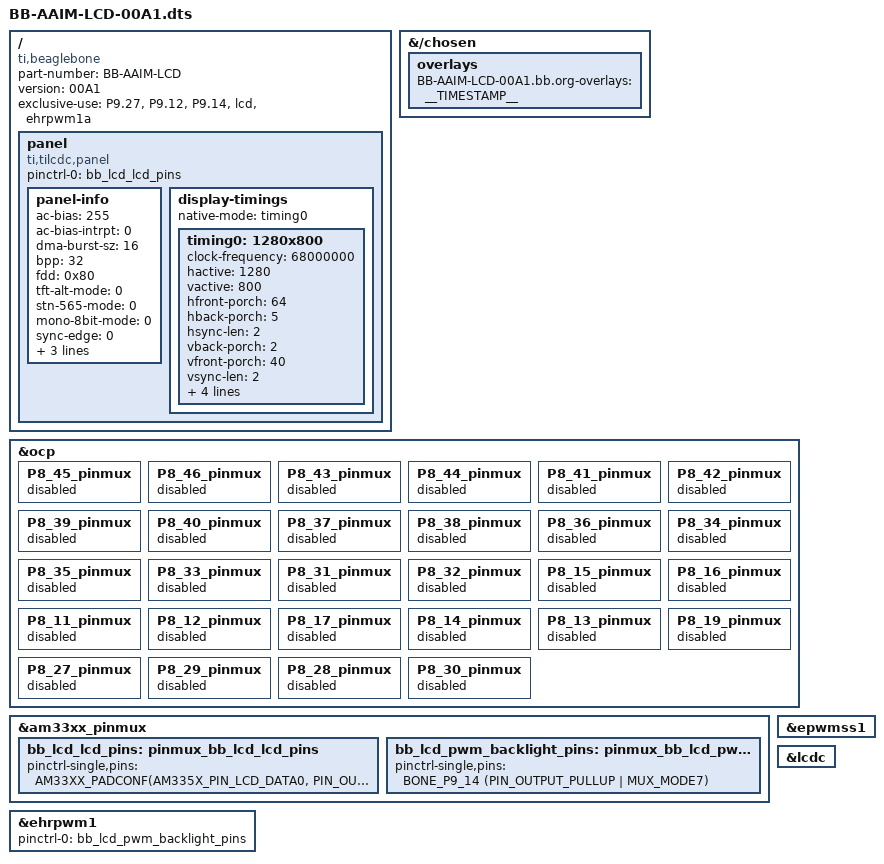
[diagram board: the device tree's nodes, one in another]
// SPDX-License-Identifier: GPL-2.0-only
/*
 * Copyright (C) 2012 Texas Instruments Incorporated - https://www.ti.com/
 */

/dts-v1/;
/plugin/;

#include <dt-bindings/board/am335x-bbw-bbb-base.h>
#include <dt-bindings/gpio/gpio.h>
#include <dt-bindings/pinctrl/am33xx.h>

/*
 * Helper to show loaded overlays under: /proc/device-tree/chosen/overlays/
 */
&{/chosen} {
	overlays {
		BB-AAIM-LCD-00A1.bb.org-overlays = __TIMESTAMP__;
	};
};

/*
 * Free up the pins used by the cape from the pinmux helpers.
 */
&ocp {
	P8_45_pinmux { status = "disabled"; };	/* lcd: lcd_data0 */
	P8_46_pinmux { status = "disabled"; };	/* lcd: lcd_data1 */
	P8_43_pinmux { status = "disabled"; };	/* lcd: lcd_data2 */
	P8_44_pinmux { status = "disabled"; };	/* lcd: lcd_data3 */
	P8_41_pinmux { status = "disabled"; };	/* lcd: lcd_data4 */
	P8_42_pinmux { status = "disabled"; };	/* lcd: lcd_data5 */
	P8_39_pinmux { status = "disabled"; };	/* lcd: lcd_data6 */
	P8_40_pinmux { status = "disabled"; };	/* lcd: lcd_data7 */
	P8_37_pinmux { status = "disabled"; };	/* lcd: lcd_data8 */
	P8_38_pinmux { status = "disabled"; };	/* lcd: lcd_data9 */
	P8_36_pinmux { status = "disabled"; };	/* lcd: lcd_data10 */
	P8_34_pinmux { status = "disabled"; };	/* lcd: lcd_data11 */
	P8_35_pinmux { status = "disabled"; };	/* lcd: lcd_data12 */
	P8_33_pinmux { status = "disabled"; };	/* lcd: lcd_data13 */
	P8_31_pinmux { status = "disabled"; };	/* lcd: lcd_data14 */
	P8_32_pinmux { status = "disabled"; };	/* lcd: lcd_data15 */

	P8_15_pinmux { status = "disabled"; };	/* gpmc_ad15.lcd_data16 */
	P8_16_pinmux { status = "disabled"; };	/* gpmc_ad14.lcd_data17 */
	P8_11_pinmux { status = "disabled"; };	/* gpmc_ad13.lcd_data18 */
	P8_12_pinmux { status = "disabled"; };	/* gpmc_ad12.lcd_data19 */
	P8_17_pinmux { status = "disabled"; };	/* gpmc_ad11.lcd_data20 */
	P8_14_pinmux { status = "disabled"; };	/* gpmc_ad10.lcd_data21 */
	P8_13_pinmux { status = "disabled"; };	/* gpmc_ad9.lcd_data22 */
	P8_19_pinmux { status = "disabled"; };	/* gpmc_ad8.lcd_data23 */

	P8_27_pinmux { status = "disabled"; };	/* lcd: lcd_vsync */
	P8_29_pinmux { status = "disabled"; };	/* lcd: lcd_hsync */
	P8_28_pinmux { status = "disabled"; };	/* lcd: lcd_pclk */
	P8_30_pinmux { status = "disabled"; };	/* lcd: lcd_ac_bias_en */
};

&am33xx_pinmux {
	bb_lcd_lcd_pins: pinmux_bb_lcd_lcd_pins {
		pinctrl-single,pins = <
			AM33XX_PADCONF(AM335X_PIN_LCD_DATA0, PIN_OUTPUT, MUX_MODE0)
			AM33XX_PADCONF(AM335X_PIN_LCD_DATA1, PIN_OUTPUT, MUX_MODE0)
			AM33XX_PADCONF(AM335X_PIN_LCD_DATA2, PIN_OUTPUT, MUX_MODE0)
			AM33XX_PADCONF(AM335X_PIN_LCD_DATA3, PIN_OUTPUT, MUX_MODE0)
			AM33XX_PADCONF(AM335X_PIN_LCD_DATA4, PIN_OUTPUT, MUX_MODE0)
			AM33XX_PADCONF(AM335X_PIN_LCD_DATA5, PIN_OUTPUT, MUX_MODE0)
			AM33XX_PADCONF(AM335X_PIN_LCD_DATA6, PIN_OUTPUT, MUX_MODE0)
			AM33XX_PADCONF(AM335X_PIN_LCD_DATA7, PIN_OUTPUT, MUX_MODE0)
			AM33XX_PADCONF(AM335X_PIN_LCD_DATA8, PIN_OUTPUT, MUX_MODE0)
			AM33XX_PADCONF(AM335X_PIN_LCD_DATA9, PIN_OUTPUT, MUX_MODE0)
			AM33XX_PADCONF(AM335X_PIN_LCD_DATA10, PIN_OUTPUT, MUX_MODE0)
			AM33XX_PADCONF(AM335X_PIN_LCD_DATA11, PIN_OUTPUT, MUX_MODE0)
			AM33XX_PADCONF(AM335X_PIN_LCD_DATA12, PIN_OUTPUT, MUX_MODE0)
			AM33XX_PADCONF(AM335X_PIN_LCD_DATA13, PIN_OUTPUT, MUX_MODE0)
			AM33XX_PADCONF(AM335X_PIN_LCD_DATA14, PIN_OUTPUT, MUX_MODE0)
			AM33XX_PADCONF(AM335X_PIN_LCD_DATA15, PIN_OUTPUT, MUX_MODE0)

			AM33XX_PADCONF(AM335X_PIN_GPMC_AD15, PIN_OUTPUT, MUX_MODE1)	/* P8_15: gpmc_ad15.lcd_data16 */
			AM33XX_PADCONF(AM335X_PIN_GPMC_AD14, PIN_OUTPUT, MUX_MODE1)	/* P8_16: gpmc_ad14.lcd_data17 */
			AM33XX_PADCONF(AM335X_PIN_GPMC_AD13, PIN_OUTPUT, MUX_MODE1)	/* P8_11: gpmc_ad13.lcd_data18 */
			AM33XX_PADCONF(AM335X_PIN_GPMC_AD12, PIN_OUTPUT, MUX_MODE1)	/* P8_12: gpmc_ad12.lcd_data19 */
			AM33XX_PADCONF(AM335X_PIN_GPMC_AD11, PIN_OUTPUT, MUX_MODE1)	/* P8_17: gpmc_ad11.lcd_data20 */
			AM33XX_PADCONF(AM335X_PIN_GPMC_AD10, PIN_OUTPUT, MUX_MODE1)	/* P8_14: gpmc_ad10.lcd_data21 */
			AM33XX_PADCONF(AM335X_PIN_GPMC_AD9, PIN_OUTPUT, MUX_MODE1)	/* P8_13: gpmc_ad9.lcd_data22 */
			AM33XX_PADCONF(AM335X_PIN_GPMC_AD8, PIN_OUTPUT, MUX_MODE1)	/* P8_19: gpmc_ad8.lcd_data23 */

			AM33XX_PADCONF(AM335X_PIN_LCD_VSYNC, PIN_OUTPUT, MUX_MODE0)
			AM33XX_PADCONF(AM335X_PIN_LCD_HSYNC, PIN_OUTPUT, MUX_MODE0)
			AM33XX_PADCONF(AM335X_PIN_LCD_PCLK, PIN_OUTPUT, MUX_MODE0)
			AM33XX_PADCONF(AM335X_PIN_LCD_AC_BIAS_EN, PIN_OUTPUT, MUX_MODE0)
		>;
	};
};

/ {
	compatible = "ti,beaglebone", "ti,beaglebone-black", "ti,beaglebone-green";

	/* identification */
	part-number = "BB-AAIM-LCD";
	version = "00A1";

	/* state the resources this cape uses */
	exclusive-use =
		/* the pin header uses */
		"P9.27",	/* lcd: gpio3_19 */
		"P9.12",	/* led: gpio1_28 */

		"P9.14",	/* pwm: ehrpwm1a */

		"lcd",
     	"ehrpwm1a"; 

	fragment@0 {
		target = <&am33xx_pinmux>;
		__overlay__ {
			bb_lcd_pwm_backlight_pins: pinmux_bb_lcd_pwm_backlight_pins {
				pinctrl-single,pins = <
					BONE_P9_14 (PIN_OUTPUT_PULLUP | MUX_MODE7) /* gpmc_a2.ehrpwm1a */
				>;
			};
		};
	};

	fragment@1 {
		target = <&epwmss1>;
		__overlay__ {
			status = "okay";
		};
	};

	fragment@2 {
		target = <&ehrpwm1>;
		__overlay__ {
			pinctrl-names = "default";
			pinctrl-0 = <&bb_lcd_pwm_backlight_pins>;
			status = "okay";
		};
	};

	fragment@3 {
		target = <&lcdc>;
		__overlay__ {
			status = "okay";
		};
	};

	fragment@4 {
		target-path="/";
		__overlay__ {

			/* avoid stupid warning */
			#address-cells = <1>;
			#size-cells = <1>;

			/* Embest 7 inch LCD cape: */
			panel {
				status = "okay";
				compatible = "ti,tilcdc,panel";
				pinctrl-names = "default";
				pinctrl-0 = <&bb_lcd_lcd_pins>;
				panel-info {
					ac-bias           = <255>;
					ac-bias-intrpt    = <0>;
					dma-burst-sz      = <16>;
					bpp               = <32>;
					fdd               = <0x80>;
					tft-alt-mode      = <0>;
					stn-565-mode      = <0>;
					mono-8bit-mode    = <0>;
					sync-edge         = <0>;
					sync-ctrl         = <0>;
					raster-order      = <1>;
					fifo-th           = <0>;
				};
				display-timings {
					native-mode = <&timing0>;
					timing0: 1280x800 {
						clock-frequency = <68000000>;
						hactive = <1280>;
						vactive = <800>;
						hfront-porch = <64>;
						hback-porch = <5>;
					    hsync-len = <2>;       /* was 30 */
						vback-porch = <2>;
						vfront-porch = <40>;
						vsync-len = <2>; 
						hsync-active = <0>;
						vsync-active  = <0>;
                        de-active = <0>;
                        pixelclk-active = <0>;
					};
				};
			};
		};
	};
};
